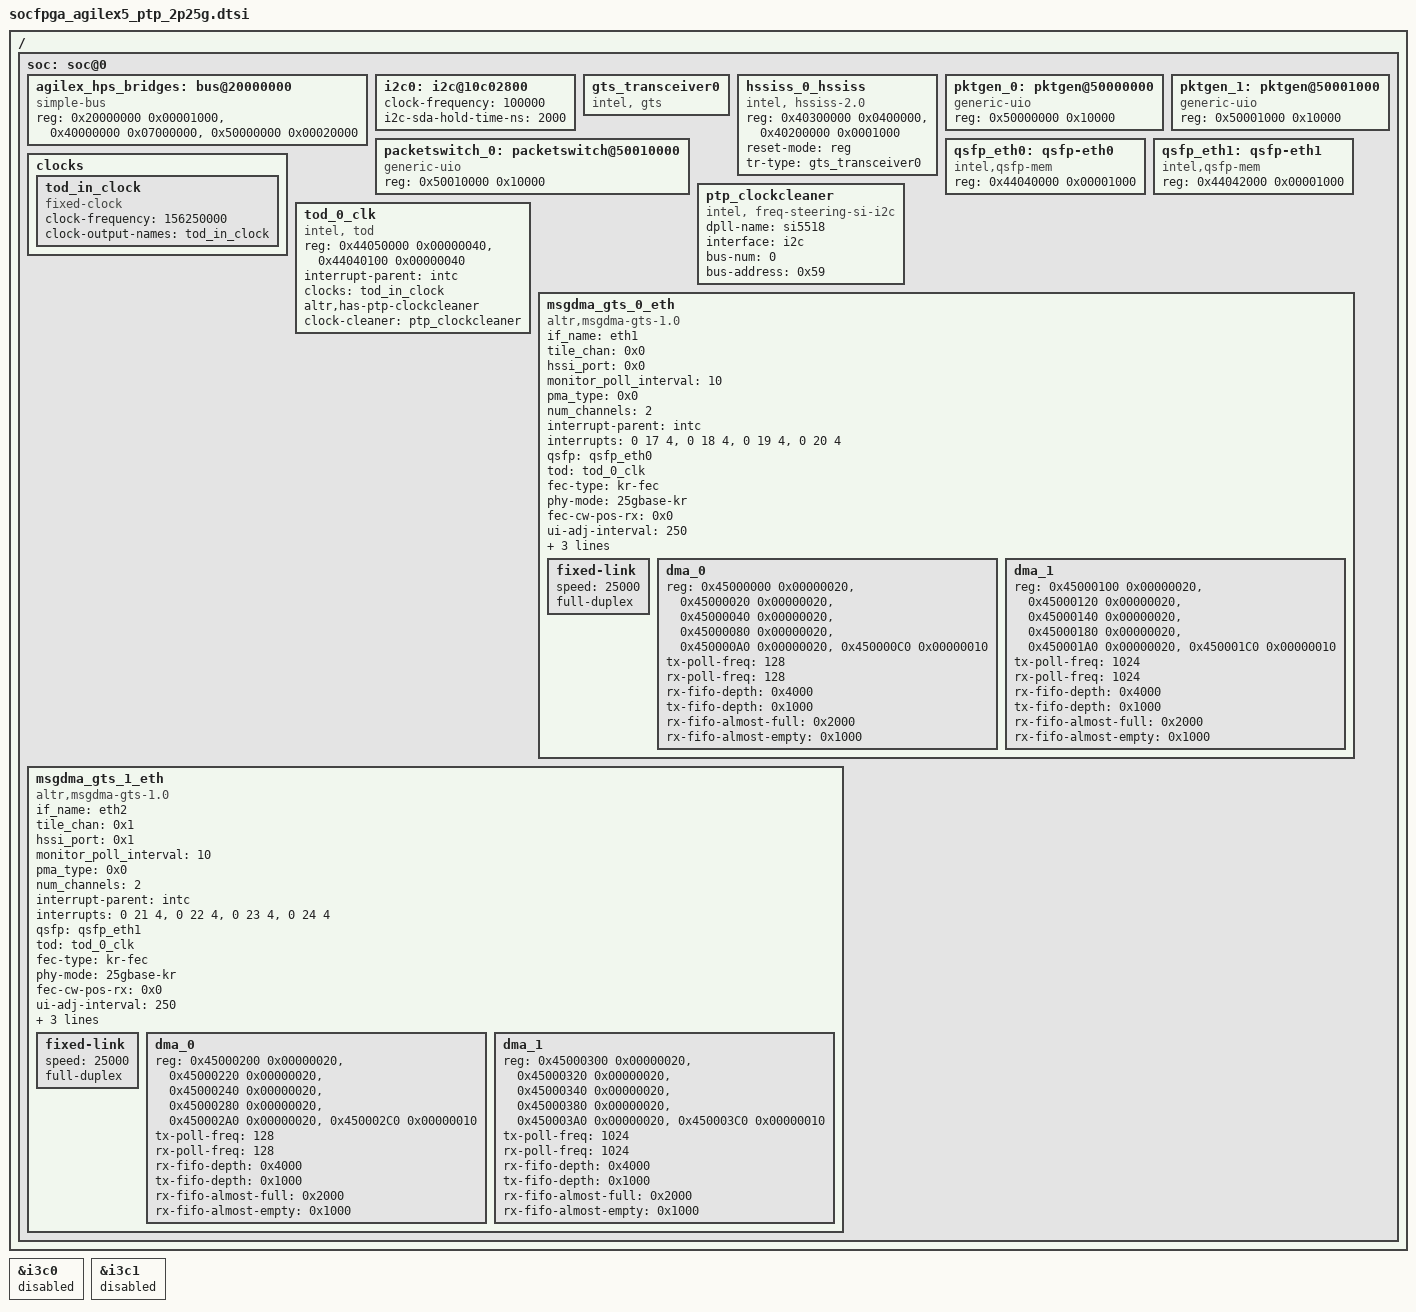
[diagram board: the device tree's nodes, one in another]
// SPDX-License-Identifier: GPL-2.0
/*
 * Copyright(C) 2024 Intel Corporation
 */

/{
	soc: soc@0{
		agilex_hps_bridges: bus@20000000 {
                compatible = "simple-bus";
                reg = <0x20000000 0x00001000>,
                      <0x40000000 0x07000000>,
		      <0x50000000 0x00020000>;
                reg-names = "axi_h2f", "axi_h2f_lw";
                #address-cells = <2>;
                #size-cells = <1>;
                ranges =    <0x00000000 0x00000000 0x20000000 0x00001000>, /*axi h2f_lw*/
                            <0x00000001 0x40000000 0x40000000 0x04000000>, /*axi_h2f: Ethernet subsytem*/
                            <0x00000001 0x44040000 0x44040000 0x00010000>, /*axi_h2f: QSFP Controller*/
                            <0x00000001 0x44050000 0x44050000 0x00000040>, /*axi_h2f: Master ToD*/
                            <0x00000001 0x45000000 0x45000000 0x00300000>, /*axi_h2f: mSGDMA Global CSR, Port CSR*/
                            <0x00000001 0x50000000 0x50000000 0x00003000>, /*axi_h2f: Port0:HE, Pkt Mux, User CSR*/
                            <0x00000001 0x50010000 0x50010000 0x00003000>; /*axi_h2f: Port1:HE, Pkt Mux, User CSR*/
		};

		i2c0: i2c@10c02800 {
			clock-frequency=<100000>;
			i2c-sda-hold-time-ns = <2000>;
			status = "okay";
                 };

		gts_transceiver0: gts_transceiver0 {
			compatible = "intel, gts";
		};

		hssiss_0_hssiss: hssiss_0_hssiss {
			compatible = "intel, hssiss-2.0";
			reg-names = "sscsr", "usr_csr";
			reg = <0x40300000 0x0400000>,
			      <0x40200000 0x0001000>;
			      
			reset-mode ="reg";
			tr-type = <&gts_transceiver0>;
		};

		pktgen_0: pktgen@50000000 {
                         compatible = "generic-uio";
                         reg = <0x50000000 0x10000>;
                         reg-names = "pkt_cli";
                };

                pktgen_1: pktgen@50001000 {
                         compatible = "generic-uio";
                         reg = <0x50001000 0x10000>;
                         reg-names = "pkt_cli";
                };

                packetswitch_0: packetswitch@50010000 {
                         compatible = "generic-uio";
                         reg = <0x50010000 0x10000>;
                         reg-names = "packetswitch";
                };

                qsfp_eth0: qsfp-eth0 {
                        compatible = "intel,qsfp-mem";
                        reg-names = "qsfp-mem-ctrl";
                        reg = <0x44040000 0x00001000>;
                        status = "okay";
                };

                qsfp_eth1: qsfp-eth1 {
                        compatible = "intel,qsfp-mem";
                        reg-names = "qsfp-mem-ctrl";
                        reg = <0x44042000 0x00001000>;
                        status = "okay";
                };

                clocks {
                        tod_in_clock: tod_in_clock {
                                #clock-cells = <0>;
                                compatible = "fixed-clock";
                                clock-frequency  = <156250000>;
                                clock-output-names = "tod_in_clock";
                        };
                };
                
		ptp_clockcleaner: ptp_clockcleaner {
                        compatible = "intel, freq-steering-si-i2c";
                        dpll-name = "si5518";
                        interface  = "i2c";
                        bus-num    = <0>;
                        bus-address = <0x59>;
                };
		
		tod_0_clk: tod_0_clk {
                        compatible = "intel, tod";
                        reg-names = "tod_ctrl",
                                    "pps_ctrl";
                        reg =  <0x44050000 0x00000040>,
                               <0x44040100 0x00000040>;
                        interrupt-parent = <&intc>;
                        clocks = <&tod_in_clock>;
                        clock-names = "tod_clock";
                        status = "okay";
                        altr,has-ptp-clockcleaner;
                        clock-cleaner = <&ptp_clockcleaner>;
                };
		
		msgdma_gts_0_eth: msgdma_gts_0_eth {
			compatible = "altr,msgdma-gts-1.0";
			#address-cells = <1>;
			#size-cells = <1>;
			ranges;
			if_name = "eth1";
			tile_chan = <0x0>;
			hssi_port = <0x0>;
			monitor_poll_interval = <10>;
			pma_type = <0x0>; // FGT - 0x00, FHT = 0x1000
			num_channels = <2>;
			interrupt-parent = <&intc>;
			interrupt-names = "dma0_tx_irq", "dma0_rx_irq", "dma1_tx_irq", "dma1_rx_irq";
			interrupts = <0 17 4>, <0 18 4>,
                                     <0 19 4>, <0 20 4>;
			status = "okay";
			qsfp = <&qsfp_eth0>;
			tod = <&tod_0_clk>;
			fec-type="kr-fec";
			phy-mode = "25gbase-kr";
			fec-cw-pos-rx = <0x0>;
			ui-adj-interval = <250>;
			hssiss = <&hssiss_0_hssiss>;
                        qsfp-lane = <0x0>;
                        altr,has-ptp;
			fixed-link {
				speed = <25000>;
				full-duplex;
			};
			dma_0 {
					reg-names =	"tx_pref"  ,
							"tx_csr"   ,
							"tx_fifo"  ,
							"rx_pref"  ,
							"rx_csr"   ,
							"rx_fifo";
					reg =	<0x45000000 0x00000020>,
						<0x45000020 0x00000020>,
						<0x45000040 0x00000020>,
						<0x45000080 0x00000020>,
						<0x450000A0 0x00000020>,
						<0x450000C0 0x00000010>;
					tx-poll-freq=<128>;
					rx-poll-freq=<128>;
					rx-fifo-depth = <0x4000>;
					tx-fifo-depth = <0x1000>;
					rx-fifo-almost-full = <0x2000>;
					rx-fifo-almost-empty = <0x1000>;
				};
			dma_1 {
					reg-names =     "tx_pref"  ,
							"tx_csr"   ,
							"tx_fifo"  ,
							"rx_pref"  ,
							"rx_csr"   ,
							"rx_fifo";
					reg =   <0x45000100 0x00000020>,
						<0x45000120 0x00000020>,
						<0x45000140 0x00000020>,
						<0x45000180 0x00000020>,
						<0x450001A0 0x00000020>,
						<0x450001C0 0x00000010>;
					tx-poll-freq=<1024>;
					rx-poll-freq=<1024>;
					rx-fifo-depth = <0x4000>;
					tx-fifo-depth = <0x1000>;
					rx-fifo-almost-full = <0x2000>;
					rx-fifo-almost-empty = <0x1000>;
				}; 
		};
		
		msgdma_gts_1_eth: msgdma_gts_1_eth {
                        compatible = "altr,msgdma-gts-1.0";
                        #address-cells = <1>;
                        #size-cells = <1>;
                        ranges;
                        if_name = "eth2";
                        tile_chan = <0x1>;
                        hssi_port = <0x1>;
                        monitor_poll_interval = <10>;
                        pma_type = <0x0>; // FGT - 0x00, FHT = 0x1000
                        num_channels = <2>;
                        interrupt-parent = <&intc>;
                        interrupt-names = "dma0_tx_irq", "dma0_rx_irq", "dma1_tx_irq", "dma1_rx_irq";
			interrupts = <0 21 4>, <0 22 4>,
                                     <0 23 4>, <0 24 4>;
                        status = "okay";
                        qsfp = <&qsfp_eth1>;
                        tod = <&tod_0_clk>;
                        fec-type="kr-fec";
                        phy-mode = "25gbase-kr";
                        fec-cw-pos-rx = <0x0>;
                        ui-adj-interval = <250>;
                        qsfp-lane = <0x0>;
                        altr,has-ptp;
                        hssiss = <&hssiss_0_hssiss>;
                        fixed-link {
                                speed = <25000>;
                                full-duplex;
                        };

			dma_0 {
					reg-names =     "tx_pref"  ,
							"tx_csr"   ,
							"tx_fifo"  ,
							"rx_pref"  ,
							"rx_csr"   ,
							"rx_fifo";

					reg =   <0x45000200 0x00000020>,
						<0x45000220 0x00000020>,
						<0x45000240 0x00000020>,
						<0x45000280 0x00000020>,
						<0x450002A0 0x00000020>,
						<0x450002C0 0x00000010>;
					tx-poll-freq=<128>;
					rx-poll-freq=<128>;
					rx-fifo-depth = <0x4000>;
					tx-fifo-depth = <0x1000>;
					rx-fifo-almost-full = <0x2000>;
					rx-fifo-almost-empty = <0x1000>;
				};
			
			dma_1 {
					reg-names =     "tx_pref"  ,
							"tx_csr"   ,
							"tx_fifo"  ,
							"rx_pref"  ,
							"rx_csr"   ,
							"rx_fifo";
					reg =   <0x45000300 0x00000020>,
						<0x45000320 0x00000020>,
						<0x45000340 0x00000020>,
						<0x45000380 0x00000020>,
						<0x450003A0 0x00000020>,
						<0x450003C0 0x00000010>;
					tx-poll-freq=<1024>;
					rx-poll-freq=<1024>;
					rx-fifo-depth = <0x4000>;
					tx-fifo-depth = <0x1000>;
					rx-fifo-almost-full = <0x2000>;
					rx-fifo-almost-empty = <0x1000>;
				};
    		 };
     };
};

&i3c0 {
	status = "disabled";
};

&i3c1 {
	status = "disabled";
};
